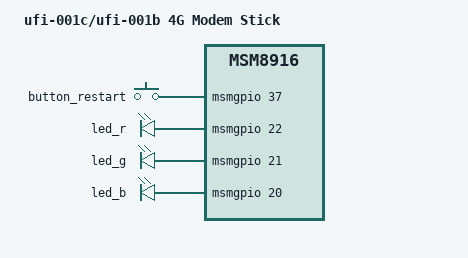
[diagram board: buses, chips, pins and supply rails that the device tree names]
// SPDX-License-Identifier: GPL-2.0-only

/dts-v1/;

#include "msm8916-ufi.dtsi"

/ {
	model = "ufi-001c/ufi-001b 4G Modem Stick";
	compatible = "thwc,ufi001c", "qcom,msm8916";
};

&button_restart {
	gpios = <&msmgpio 37 GPIO_ACTIVE_HIGH>;
};

&led_r {
	gpios = <&msmgpio 22 GPIO_ACTIVE_HIGH>;
};

&led_g {
	gpios = <&msmgpio 21 GPIO_ACTIVE_HIGH>;
};

&led_b {
	gpios = <&msmgpio 20 GPIO_ACTIVE_HIGH>;
};

&mpss {
	pinctrl-0 = <&sim_ctrl_default>;
	pinctrl-names = "default";
};

&button_default {
	pins = "gpio37";
	bias-pull-down;
};

&gpio_leds_default {
	pins = "gpio20", "gpio21", "gpio22";
};

/* This selects the external SIM card slot by default */
&msmgpio {
	sim_ctrl_default: sim-ctrl-default-state {
		esim-sel-pins {
			pins = "gpio0", "gpio3";
			bias-disable;
			output-low;
		};

		sim-en-pins {
			pins = "gpio1";
			bias-disable;
			output-low;
		};

		sim-sel-pins {
			pins = "gpio2";
			bias-disable;
			output-high;
		};
	};
};

&memshare {
        /delete-property/ qcom,legacy-client;
};

/delete-node/ &memshare_gps;
/delete-node/ &gps_mem;
/delete-node/ &mdss;
/delete-node/ &gpu;
/delete-node/ &gpu_iommu;
/delete-node/ &sound;
/delete-node/ &lpass;
/delete-node/ &lpass_codec;
/delete-node/ &wcnss_bt;
/delete-node/ &pm8916_codec;
/delete-node/ &venus;
/delete-node/ &venus_mem;
/delete-node/ &camss;
/delete-node/ &{/thermal-zones/gpu-thermal};
/delete-node/ &{/thermal-zones/camera-thermal};
